# FM33L0XX register map
File version: 1.0
CPU: SC000 r1p0, little endian, no MPU, no FPU, 3 interrupt priority bits
Registers are 32-bit, read-write, reset 0x0 unless marked. A register's access mark holds for its fields unless they carry their own. Offsets are from the block's base; [hi:lo] are bit positions; 'fields as' and 'values as' point back to an identical list.

## I2C — I2C Registers
Base 0x40012400
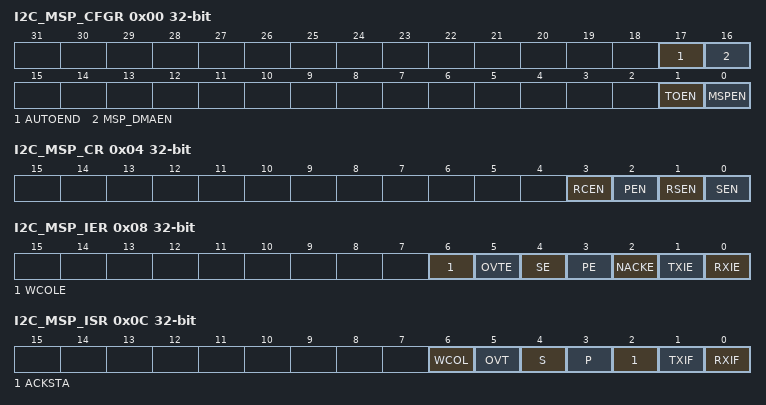
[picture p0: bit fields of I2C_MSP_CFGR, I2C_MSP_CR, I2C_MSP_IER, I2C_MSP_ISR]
0x00 I2C_MSP_CFGR — I2C CONTROL REGISTER
  [all] fields
    0=DISABLE; 1=ENABLE
  [17] AUTOEND
  [16] MSP_DMAEN
  [1] TOEN
  [0] MSPEN
0x04 I2C_MSP_CR — MSP_CON
  [all] fields
    0=DISABLE; 1=ENABLE
  [3] RCEN — RECEIVE ENABLE
  [2] PEN
  [1] RSEN
  [0] SEN
0x08 I2C_MSP_IER — MSP_IE
  [all] fields
    0=DISABLE; 1=ENABLE
  [6] WCOLE
  [5] OVTE
  [4] SE
  [3] PE
  [2] NACKE
  [1] TXIE
  [0] RXIE
0x0C I2C_MSP_ISR
  [6] WCOL
    0=DISABLE; 1=ENABLE
  [5] OVT
    0=DISABLE; 1=ENABLE
  [4] S
    0=DISABLE; 1=ENABLE
  [3] P
    0=DISABLE; 1=ENABLE
  [2] ACKSTA
    0=DISABLE; 1=ENABLE
  [1] TXIF
    0=DISABLE; 1=ENABLE
  [0] RXIF
    0=RESET; 1=SET
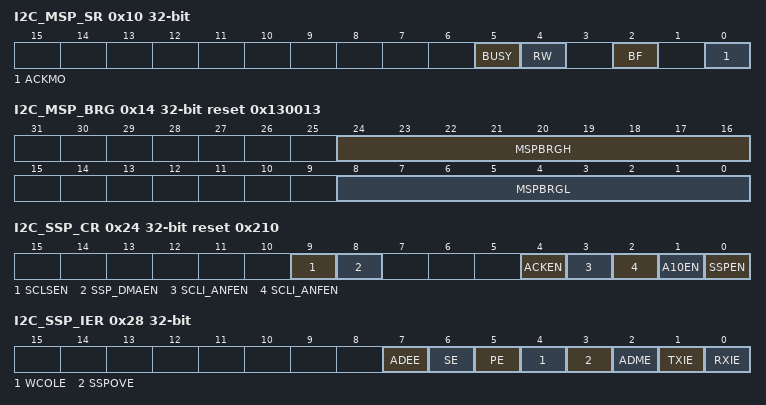
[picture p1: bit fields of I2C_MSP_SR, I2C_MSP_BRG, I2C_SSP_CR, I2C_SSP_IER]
0x10 I2C_MSP_SR
  [5] BUSY ro
  [4] RW ro
  [2] BF ro — BUFF FULL
    0=EMPTY (SSPBUF EMPTY); 1=FULL (SSPBUF FULL)
  [0] ACKMO — Ack Master output
    0=MRP0 (MASTER RESPOND 0); 1=MRPN (MASTER RESPOND NONE)
0x14 I2C_MSP_BRG reset 0x130013 — MSP_BRG
  [24:16] MSPBRGH, [8:0] MSPBRGL
0x18 I2CBUF
  [7:0] MSPBUF
0x1C MSP_TIMING reset 0xA
  [8:0] SDAHD — SDA HOLD TIME
0x20 TIMEOUT reset 0xFFF
  [11:0] TIMEOUT
0x24 I2C_SSP_CR reset 0x210
  [9] SCLSEN
  [8] SSP_DMAEN
  [4] ACKEN — SCLI_ANFEN
  [3] SCLI_ANFEN
  [2] SCLI_ANFEN
  [1] A10EN
  [0] SSPEN
    0=DISABLE; 1=ENABLE
0x28 I2C_SSP_IER
  [7] ADEE — SE
  [6] SE
  [5] PE
  [4] WCOLE
  [3] SSPOVE
  [2] ADME
  [1] TXIE
  [0] RXIE
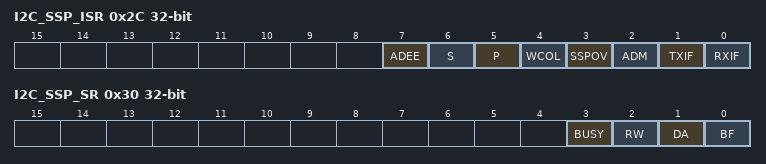
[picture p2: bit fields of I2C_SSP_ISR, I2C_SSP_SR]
0x2C I2C_SSP_ISR
  [7] ADEE — SE
  [6] S ro
  [5] P ro
  [4] WCOL — WCOLE
  [3] SSPOV
  [2] ADM
  [1] TXIF
  [0] RXIF
0x30 I2C_SSP_SR — I2C_SSP_ISR
  [3] BUSY ro, [2] RW ro, [1] DA ro, [0] BF ro
0x34 I2C_SSP_SR — I2C_SSP_ISR
  [7:0] SSPBUF
0x38 I2C_SSP_ADR
  [9:0] SSPBUF

## RCC_PDR — RCC_PDR Registers
Base 0x40012800
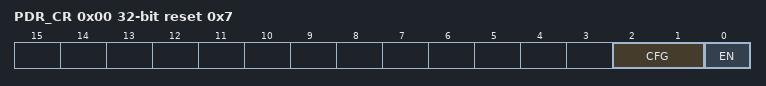
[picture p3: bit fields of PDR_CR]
0x00 PDR_CR reset 0x7 — PDR CONFIG REGISTER
  [2:1] CFG — PDR CONFIG
    0=1.5V; 1=1.25V; 2=1.35V; 3=1.4V
  [0] EN — PDR ENABLE

## RCC_BOR — RCC_BOR Registers
Base 0x40012804
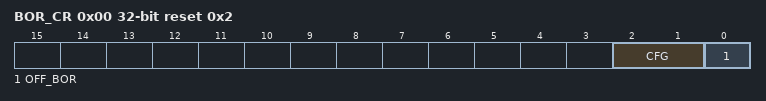
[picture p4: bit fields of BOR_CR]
0x00 BOR_CR reset 0x2 — BOR CONFIG REGISTER
  [2:1] CFG — BOR CONFIG
    0=1.7V; 1=1.6V; 2=1.65V; 3=1.75V
  [0] OFF_BOR — BOR OFF ENABLE

## SVD — SVD Registers
Base 0x40012824
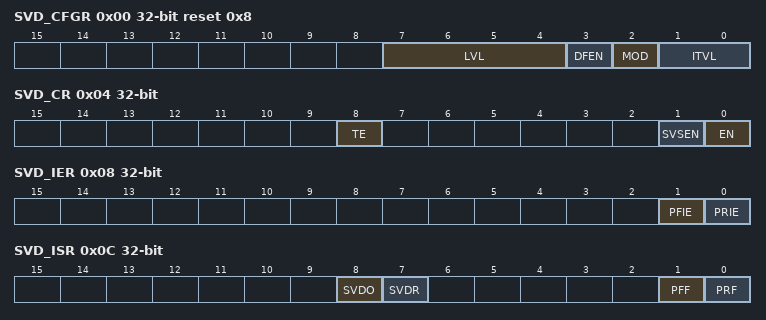
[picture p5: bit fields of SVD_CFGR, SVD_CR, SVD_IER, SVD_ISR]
0x00 SVD_CFGR reset 0x8 — SVD CONFIG REGISTER
  [7:4] LVL — SVD ALARM LEVEL
  [3] DFEN — SVD DIGITAL FILTER ENABLE
  [2] MOD — MODE
    0=IMTEN (INTERMITTENT ENABLE); 1=OFTEN (OFTEN ENABLE)
  [1:0] ITVL — SVD Interval
    0=62.5ms; 1=256ms; 2=1s; 3=4s
0x04 SVD_CR — SVD CONTROL REGISTER
  [8] TE — SVD TEST EENABLE
  [1] SVSEN — SVS ENABLE
  [0] EN — SVD ENABLE
0x08 SVD_IER
  [1] PFIE, [0] PRIE
0x0C SVD_ISR — SVD STATUS AND IF
  [8] SVDO ro — SVD OUTPUT
  [7] SVDR ro — SVD OUTPUT LATCH
  [1] PFF
  [0] PRF
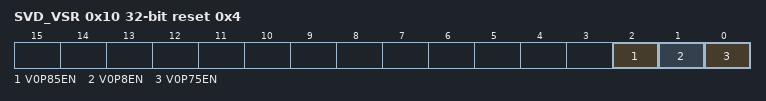
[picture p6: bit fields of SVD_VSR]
0x10 SVD_VSR reset 0x4
  [all] fields
    0=DISABLE; 1=ENABLE
  [2] V0P85EN
  [1] V0P8EN
  [0] V0P75EN

## RCC_FDET — RCC_FDET Registers
Base 0x40012838
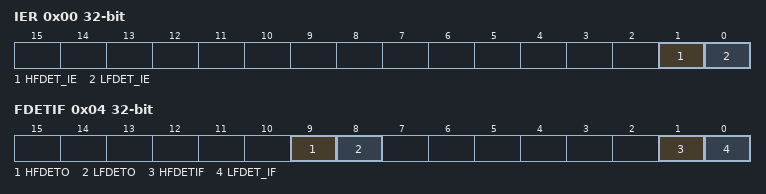
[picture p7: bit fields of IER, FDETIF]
0x00 IER — XTLF FREQ DETECT IE
  [1] HFDET_IE
  [0] LFDET_IE — XTLF FREQ DETECT IE
0x04 FDETIF — XTLF FREQ DETECT IF
  [9] HFDETO, [8] LFDETO, [1] HFDETIF, [0] LFDET_IF

## OPA1 — OPA1 Registers
Base 0x40012844
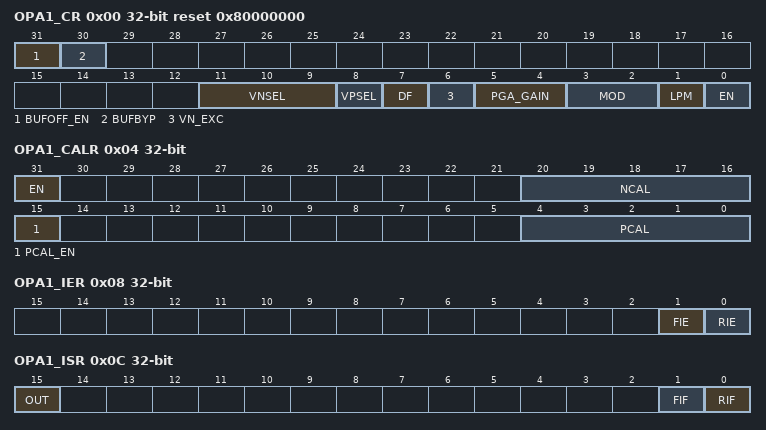
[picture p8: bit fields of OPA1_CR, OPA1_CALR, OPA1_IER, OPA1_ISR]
0x00 OPA1_CR reset 0x80000000 — COMP1 CONTROL REGISTER
  [31] BUFOFF_EN — BUFENB
    0=DISABLE; 1=ENABLE
  [30] BUFBYP
    0=DISABLE; 1=ENABLE
  [11:9] VNSEL
    0=OPA1_INN1; 1=OPA1_INN2; 2=VREF; 3=3/4 VREF; 4=1/2 VREF; 5=1/4 VREF; 6=1/8 VREF
  [8] VPSEL
    0=OPA1_INP1; 1=OPA1_INP2
  [7] DF — COMP1DF
    0=DISABLE; 1=ENABLE
  [6] VN_EXC
    0=NOT CONNECT GPIO; 1=CONNECT GPIO
  [5:4] PGA_GAIN
    0=PGA*2; 1=PGA*4; 2=PGA*8; 3=PGA*16
  [3:2] MOD — OPA1MOD
    0=standalone MODE; 1=COMP MODE; 2=PGA MODE; 3=buffer MODE
  [1] LPM — OPA1LPM
    0=NORMAL MODE; 1=LOW POWER MODE
  [0] EN
    0=DISABLE; 1=ENABLE
0x04 OPA1_CALR
  [31] EN — NCAL_EN
    0=DISABLE; 1=ENABLE
  [20:16] NCAL
    0=NOT CHANGE; 1=DECREASE_MIN; 15=DECREASE_MAX; 16=NOT CHANGE; 17=ADD_MIN; 31=ADD_MAX
  [15] PCAL_EN
    0=DISABLE; 1=ENABLE
  [4:0] PCAL
    values as NCAL
0x08 OPA1_IER — COMP IE REGISTER
  [1] FIE — COMP1FIE
    0=DISABLE; 1=ENABLE
  [0] RIE — COMP1RIE
    0=DISABLE; 1=ENABLE
0x0C OPA1_ISR — COMP IF REGISTER
  [15] OUT ro — COMP1O
  [1] FIF — COMP1FIF
    0=DISABLE; 1=ENABLE
  [0] RIF — COMP1RIF
    0=RESET; 1=SET
